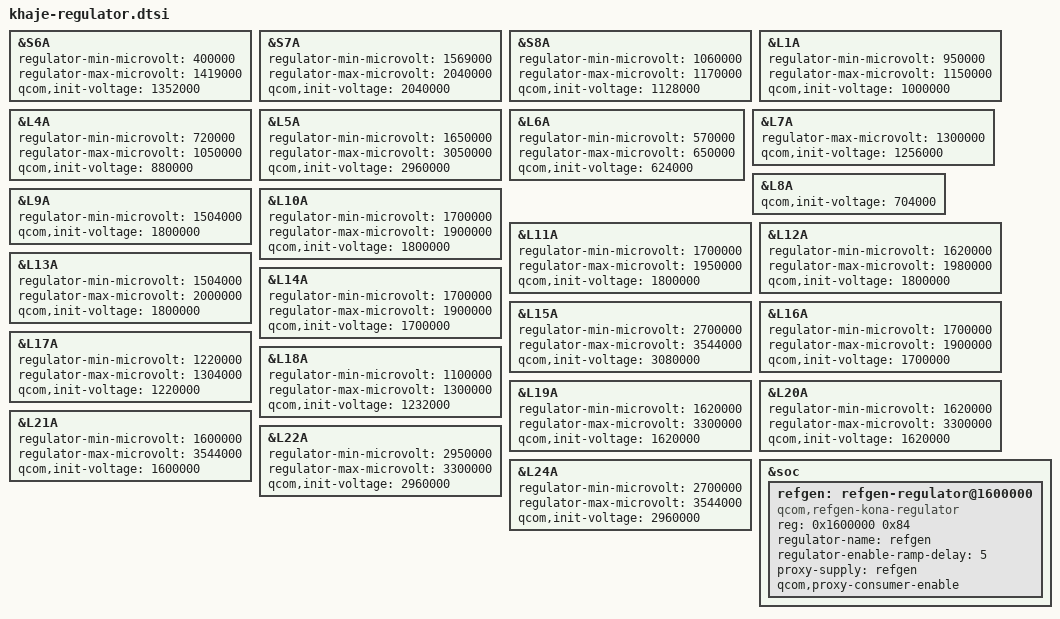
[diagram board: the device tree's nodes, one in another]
#include "bengal-regulator.dtsi"

&S6A {
	regulator-min-microvolt = <400000>;
	regulator-max-microvolt = <1419000>;
	qcom,init-voltage = <1352000>;
};

&S7A {
	regulator-min-microvolt = <1569000>;
	regulator-max-microvolt = <2040000>;
	qcom,init-voltage = <2040000>;
};

&S8A {
	regulator-min-microvolt = <1060000>;
	regulator-max-microvolt = <1170000>;
	qcom,init-voltage = <1128000>;
};

&L1A {
	regulator-min-microvolt = <950000>;
	regulator-max-microvolt = <1150000>;
	qcom,init-voltage = <1000000>;
};

&L4A {
	regulator-min-microvolt = <720000>;
	regulator-max-microvolt = <1050000>;
	qcom,init-voltage = <880000>;
};

&L5A {
	regulator-min-microvolt = <1650000>;
	regulator-max-microvolt = <3050000>;
	qcom,init-voltage = <2960000>;
};

&L6A {
	regulator-min-microvolt = <570000>;
	regulator-max-microvolt = <650000>;
	qcom,init-voltage = <624000>;
};

&L7A {
	regulator-max-microvolt = <1300000>;
	qcom,init-voltage = <1256000>;
};

&L8A {
	qcom,init-voltage = <704000>;
};

&L9A {
	regulator-min-microvolt = <1504000>;
	qcom,init-voltage = <1800000>;
};

&L10A {
	regulator-min-microvolt = <1700000>;
	regulator-max-microvolt = <1900000>;
	qcom,init-voltage = <1800000>;
};

&L11A {
	regulator-min-microvolt = <1700000>;
	regulator-max-microvolt = <1950000>;
	qcom,init-voltage = <1800000>;
};

&L12A {
	regulator-min-microvolt = <1620000>;
	regulator-max-microvolt = <1980000>;
	qcom,init-voltage = <1800000>;
};

&L13A {
	regulator-min-microvolt = <1504000>;
	regulator-max-microvolt = <2000000>;
	qcom,init-voltage = <1800000>;
};

&L14A {
	regulator-min-microvolt = <1700000>;
	regulator-max-microvolt = <1900000>;
	qcom,init-voltage = <1700000>;
};

&L15A {
	regulator-min-microvolt = <2700000>;
	regulator-max-microvolt = <3544000>;
	qcom,init-voltage = <3080000>;
};

&L16A {
	regulator-min-microvolt = <1700000>;
	regulator-max-microvolt = <1900000>;
	qcom,init-voltage = <1700000>;
};

&L17A {
	regulator-min-microvolt = <1220000>;
	regulator-max-microvolt = <1304000>;
	qcom,init-voltage = <1220000>;
};

&L18A {
	regulator-min-microvolt = <1100000>;
	regulator-max-microvolt = <1300000>;
	qcom,init-voltage = <1232000>;
};

&L19A {
	regulator-min-microvolt = <1620000>;
	regulator-max-microvolt = <3300000>;
	qcom,init-voltage = <1620000>;
};

&L20A {
	regulator-min-microvolt = <1620000>;
	regulator-max-microvolt = <3300000>;
	qcom,init-voltage = <1620000>;
};

&L21A {
	regulator-min-microvolt = <1600000>;
	regulator-max-microvolt = <3544000>;
	qcom,init-voltage = <1600000>;
};

&L22A {
	regulator-min-microvolt = <2950000>;
	regulator-max-microvolt = <3300000>;
	qcom,init-voltage = <2960000>;
};

&L24A {
	regulator-min-microvolt = <2700000>;
	regulator-max-microvolt = <3544000>;
	qcom,init-voltage = <2960000>;
};

&soc {
	refgen: refgen-regulator@1600000 {
		compatible = "qcom,refgen-kona-regulator";
		reg = <0x1600000 0x84>;
		regulator-name = "refgen";
		regulator-enable-ramp-delay = <5>;
		proxy-supply = <&refgen>;
		qcom,proxy-consumer-enable;
	};
};
